# STM32WBA55 register map
File version: 1.0
CPU: CM33 r0p1, little endian, MPU, FPU, 4 interrupt priority bits
Registers are 32-bit, read-write, reset 0x0 unless marked. A register's access mark holds for its fields unless they carry their own. Offsets are from the block's base; [hi:lo] are bit positions; {n}, {i} and the like mark numbered series; 'fields as' and 'values as' point back to an identical list.

## GPIOC — General-purpose I/Os
Base 0x42020800
Same registers: SEC_GPIOC 0x52020800
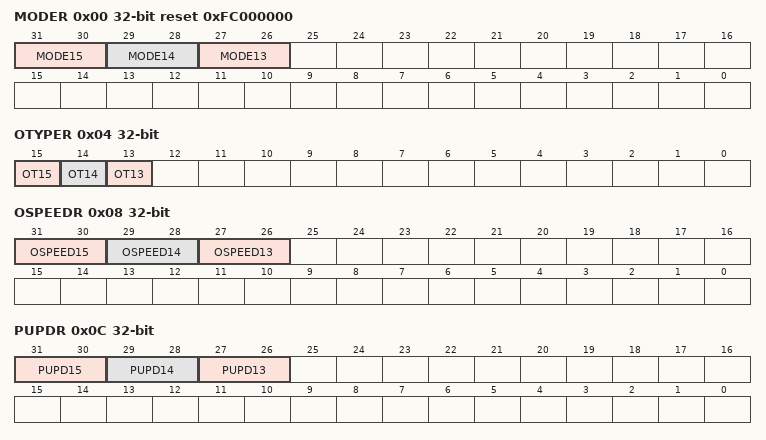
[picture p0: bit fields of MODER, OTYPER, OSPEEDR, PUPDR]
0x00 MODER reset 0xFC000000 — GPIO port C mode register
  [all] fields
    0=Input mode; 1=Output (General purpose output mode); 2=Alternate function mode; 3=Analog mode
  [31:30] MODE15 — Port C configuration I/O pin 15 These bits are written by software to configure the I/O mode. Access can be protected by GPIOC SEC15.
  [29:28] MODE14 — Port C configuration I/O pin 14
  [27:26] MODE13 — Port C configuration I/O pin 13
0x04 OTYPER — GPIO port C output type register
  [all] fields
    0=PushPull (Output push-pull (reset state)); 1=OpenDrain (Output open-drain)
  [15] OT15 — Port C configuration I/O pin y These bits are written by software to configure the I/O output type. Access can be protected by GPIOC SECy.
  [14] OT14 — Port C configuration I/O pin y These bits are written by software to configure the I/O output type. Access can be protected by GPIOC SECy.
  [13] OT13 — Port C configuration I/O pin y These bits are written by software to configure the I/O output type. Access can be protected by GPIOC SECy.
0x08 OSPEEDR — GPIOC port output speed register
  [all] fields
    0=LowSpeed; 1=MediumSpeed; 2=HighSpeed; 3=VeryHighSpeed
  [31:30] OSPEED15 — Port C configuration I/O pin 15 These bits are written by software to configure the I/O output speed. Access can be protected by GPIOC SEC15. Note: Refer to the device datasheet for the frequency specifications and the power supply and load conditions for each speed.
  [29:28] OSPEED14 — Port C configuration I/O pin 14
  [27:26] OSPEED13 — Port C configuration I/O pin 13
0x0C PUPDR — GPIO port C pull-up/pull-down register
  [all] fields
    0=Floating (No pull-up, pull-down); 1=PullUp; 2=PullDown
  [31:30] PUPD15 — Port C configuration I/O pin 15 These bits are written by software to configure the I/O pull-up or pull-down Access can be protected by GPIOC SEC15.
  [29:28] PUPD14 — Port C configuration I/O pin 14
  [27:26] PUPD13 — Port C configuration I/O pin 13
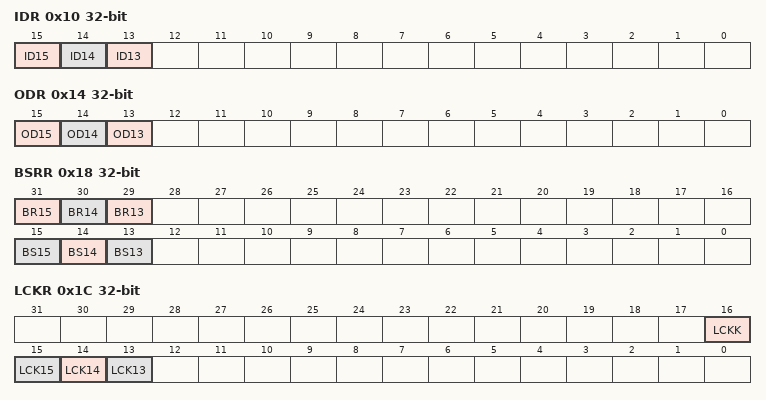
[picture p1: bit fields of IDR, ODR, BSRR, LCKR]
0x10 IDR ro (reset mask 0xFFFF0FFF) — GPIO port C input data register
  [all] fields
    0=Low (Input is logic low); 1=High (Input is logic high)
  [15] ID15 — Port C input data I/O pin y These bits are read-only. They contain the input value of the corresponding I/O port. Access can be protected by GPIOC SECy.
  [14] ID14 — Port C input data I/O pin y These bits are read-only. They contain the input value of the corresponding I/O port. Access can be protected by GPIOC SECy.
  [13] ID13 — Port C input data I/O pin y These bits are read-only. They contain the input value of the corresponding I/O port. Access can be protected by GPIOC SECy.
0x14 ODR — GPIO port C output data register
  [all] fields
    0=Low (Set output to logic low); 1=High (Set output to logic high)
  [15] OD15 — Port C output data I/O pin y These bits can be read and written by software. Access can be protected by GPIOC SECy. Note: For atomic bit set/reset, the OD bits can be individually set and/or reset by writing to the GPIOC_BSRR or GPIOC_BRR registers.
  [14] OD14 — Port C output data I/O pin y These bits can be read and written by software. Access can be protected by GPIOC SECy. Note: For atomic bit set/reset, the OD bits can be individually set and/or reset by writing to the GPIOC_BSRR or GPIOC_BRR registers.
  [13] OD13 — Port C output data I/O pin y These bits can be read and written by software. Access can be protected by GPIOC SECy. Note: For atomic bit set/reset, the OD bits can be individually set and/or reset by writing to the GPIOC_BSRR or GPIOC_BRR registers.
0x18 BSRR wo — GPIO port C bit set/reset register
  [31] BR15 — Port C reset I/O pin y These bits are write-only. A read to these bits returns the value 0. Access can be protected by GPIOC SECy. Note: If both BSy and BRy are set, BSy has priority.
    1=Resets the corresponding ODx bit
  [30] BR14 — Port C reset I/O pin y These bits are write-only. A read to these bits returns the value 0. Access can be protected by GPIOC SECy. Note: If both BSy and BRy are set, BSy has priority.
    1=Resets the corresponding ODx bit
  [29] BR13 — Port C reset I/O pin y These bits are write-only. A read to these bits returns the value 0. Access can be protected by GPIOC SECy. Note: If both BSy and BRy are set, BSy has priority.
    1=Resets the corresponding ODx bit
  [15] BS15 — Port C set I/O pin y These bits are write-only. A read to these bits returns the value 0. Access can be protected by GPIOC SECy.
    1=Set (Sets the corresponding ODx bit)
  [14] BS14 — Port C set I/O pin y These bits are write-only. A read to these bits returns the value 0. Access can be protected by GPIOC SECy.
    1=Set (Sets the corresponding ODx bit)
  [13] BS13 — Port C set I/O pin y These bits are write-only. A read to these bits returns the value 0. Access can be protected by GPIOC SECy.
    1=Set (Sets the corresponding ODx bit)
0x1C LCKR — GPIO port C configuration lock register
  [16] LCKK — Lock key This bit can be read any time. It can only be modified using the lock key write sequence. Access is protected by any GPIOC SECy. - LOCK key write sequence: WR LCKR[16] = 1 + LCKR[15:13] WR LCKR[16] = 0 + LCKR[15:13] WR LCKR[16] = 1 + LCKR[15:13] - LOCK key read RD LCKR[16] = 1 (this read operation is optional but it confirms that the lock is active) Note: During the LOCK key write sequence, the value of LCK[15:13] must not change. Note: Any error in the lock sequence aborts the LOCK. Note: After the first LOCK sequence on any bit of the port, any read access on the LCKK bit returns 1 until the next MCU reset or peripheral reset.
    0=NotActive (Port configuration lock key not active); 1=Active (Port configuration lock key active)
  [15] LCK15 — Port C lock I/O pin y These bits are read/write but can only be written when the LCKK bit is 0 Access can be protected by GPIOC SECy.
    0=Unlocked (Port configuration not locked); 1=Locked (Port configuration locked)
  [14] LCK14 — Port C lock I/O pin y These bits are read/write but can only be written when the LCKK bit is 0 Access can be protected by GPIOC SECy.
    values as LCK15
  [13] LCK13 — Port C lock I/O pin y These bits are read/write but can only be written when the LCKK bit is 0 Access can be protected by GPIOC SECy.
    values as LCK15
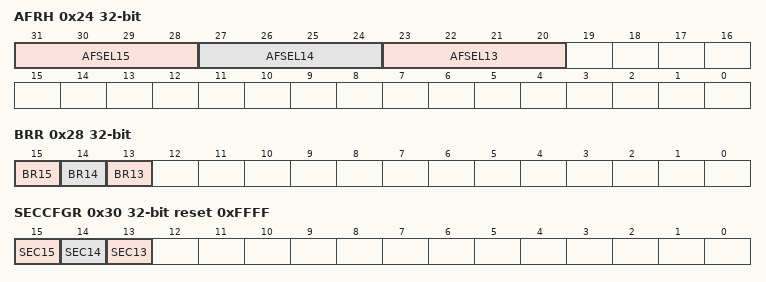
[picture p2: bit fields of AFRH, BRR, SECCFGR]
0x24 AFRH — GPIO port C alternate function high register
  [all] fields
    {v}=AF{v} (v=0..15)
  [31:28] AFSEL15 — Alternate function selection for port C I/O pin 15 These bits are written by software to configure alternate function I/Os. Access can be protected by GPIOC SEC15.
  [27:24] AFSEL14 — Alternate function selection for port C I/O pin 14
  [23:20] AFSEL13 — Alternate function selection for port C I/O pin 13
0x28 BRR wo — GPIO port C bit reset register
  [15] BR15 — Port reset I/O pin y These bits are write-only. A read to these bits returns the value 0. Access can be protected by GPIOC SECy.
    1=Resets the corresponding ODx bit
  [14] BR14 — Port reset I/O pin y These bits are write-only. A read to these bits returns the value 0. Access can be protected by GPIOC SECy.
    1=Resets the corresponding ODx bit
  [13] BR13 — Port reset I/O pin y These bits are write-only. A read to these bits returns the value 0. Access can be protected by GPIOC SECy.
    0=No action on the corresponding ODx bit; 1=Reset the ODx bit
0x30 SECCFGR wo reset 0xFFFF — GPIO port C secure configuration register
  [all] fields
    0=NonSecure (The I/O pin is non-secure); 1=Secure (The I/O pin is secure)
  [15] SEC15 — I/O pin of port C secure bit enable y These bits are written by software to enabled the security I/O port pin.
  [14] SEC14 — I/O pin of port C secure bit enable y These bits are written by software to enabled the security I/O port pin.
  [13] SEC13 — I/O pin of port C secure bit enable y These bits are written by software to enabled the security I/O port pin.
